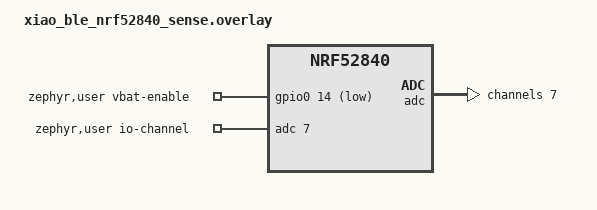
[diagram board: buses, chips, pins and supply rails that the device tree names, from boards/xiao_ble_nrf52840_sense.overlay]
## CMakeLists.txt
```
# AeroDrag Wheel — Zephyr application.
# Firmware SEPARATO (nRF52840) — NON fa parte del build ESP-IDF della repo madre.
cmake_minimum_required(VERSION 3.20.0)

find_package(Zephyr REQUIRED HINTS $ENV{ZEPHYR_BASE})
project(aerodrag_wheel)

target_sources(app PRIVATE
	src/main.c
	src/wheel_ble.c
	src/wheel_battery.c
	src/wheel_store.c
)
```

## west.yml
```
# AeroDrag Wheel — manifest west (app standalone su nRF Connect SDK).
#
# Uso (workspace-app, topologia T2):
#   west init -l .            # inizializza il workspace usando questo manifest
#   west update               # scarica NCS/Zephyr alla revisione sotto
#   west build -b xiao_ble/nrf52840/sense
#
# La revisione NCS è pinnata per riproducibilità: adeguala a quella che hai
# installato localmente se necessario (vedi README → bring-up).
manifest:
  remotes:
    - name: nrfconnect
      url-base: https://github.com/nrfconnect
  projects:
    - name: sdk-nrf
      remote: nrfconnect
      revision: v2.7.0
      import: true
  self:
    path: aerodrag-wheel
```

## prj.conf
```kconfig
# AeroDrag Wheel — Zephyr / nRF Connect SDK config
# Board: XIAO BLE Sense (xiao_ble/nrf52840/sense) — IMU LSM6DS3TR-C onboard + LiPo.

# ── BLE peripheral ───────────────────────────────────────────────────────────
CONFIG_BT=y
CONFIG_BT_PERIPHERAL=y
CONFIG_BT_DEVICE_NAME="AeroDrag Wheel"
CONFIG_BT_MAX_CONN=2
CONFIG_BT_GATT_CLIENT=n
CONFIG_BT_GATT_DYNAMIC_DB=y

# Bonding/cifratura del confine G (contract v0.3.4 §2.G): il link 0xBB00 DEVE essere
# cifrato + bondato (LE SM1, Level >=2). Just Works / NoInputNoOutput (default: nessun
# auth-cb con display/input) -> Level 2 *unauthenticated*, coerente col central ESP32
# (sm_sc=1, sm_mitm=0, NoInputNoOutput, key_dist ENC|ID, indirizzo pubblico statico).
# NON abilitare SC-only (CONFIG_BT_SMP_SC_PAIR_ONLY) o MITM qui: e' il passo 4
# anti-downgrade del rollout (seam #21); unilaterale staccherebbe il pairing.
CONFIG_BT_SMP=y
CONFIG_BT_BONDABLE=y
CONFIG_BT_SETTINGS=y
CONFIG_BT_FILTER_ACCEPT_LIST=y
CONFIG_BT_MAX_PAIRED=2

# Battery Service standard (0x180F) — addizione non-breaking, utile lato prodotto.
CONFIG_BT_BAS=y

# ── IMU onboard LSM6DS3TR-C (I2C interno) ───────────────────────────────────
# Il LSM6DS3TR-C è register-compatibile con la famiglia LSM6DSL. Se la tua
# versione di NCS dichiara l'IMU con un altro compatible, adegua qui (vedi README).
CONFIG_SENSOR=y
CONFIG_I2C=y
CONFIG_LSM6DSL=y
CONFIG_LSM6DSL_ENABLE_TEMP=y

# ── ADC + GPIO (lettura batteria LiPo del XIAO) ─────────────────────────────
CONFIG_ADC=y
CONFIG_GPIO=y

# ── Persistenza config + bond (Settings su NVS/flash) ───────────────────────
CONFIG_FLASH=y
CONFIG_FLASH_MAP=y
CONFIG_NVS=y
CONFIG_SETTINGS=y

# ── Floating point + stampa %f nei log ──────────────────────────────────────
CONFIG_FPU=y
CONFIG_CBPRINTF_FP_SUPPORT=y

# ── Stack ────────────────────────────────────────────────────────────────────
CONFIG_MAIN_STACK_SIZE=4096
CONFIG_SYSTEM_WORKQUEUE_STACK_SIZE=2048

# ── Logging ──────────────────────────────────────────────────────────────────
CONFIG_LOG=y
```

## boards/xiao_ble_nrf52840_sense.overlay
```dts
/*
 * Overlay XIAO BLE Sense — lettura batteria LiPo.
 *
 * Sul XIAO nRF52840 la tensione di batteria è su un partitore: il canale ADC è
 * AIN7 (P0.31) e l'enable del partitore è P0.14 (attivo basso). Verifica i pin
 * e il rapporto del partitore sulla TUA revisione board (vedi README/bring-up).
 *
 * L'IMU LSM6DS3TR-C è già dichiarata dalla board variant `/sense`: qui non serve
 * ridefinirla. Se la tua DTS non espone l'alias 'imu', il firmware usa comunque
 * il primo nodo st,lsm6dsl/lsm6dso okay (vedi src/main.c).
 */
#include <zephyr/dt-bindings/adc/adc.h>
#include <zephyr/dt-bindings/adc/nrf-saadc.h>
#include <zephyr/dt-bindings/gpio/gpio.h>

/ {
	zephyr,user {
		io-channels = <&adc 7>;
		vbat-enable-gpios = <&gpio0 14 GPIO_ACTIVE_LOW>;
	};
};

&adc {
	status = "okay";
	#address-cells = <1>;
	#size-cells = <0>;

	channel@7 {
		reg = <7>;
		zephyr,gain = "ADC_GAIN_1_6";
		zephyr,reference = "ADC_REF_INTERNAL";
		zephyr,acquisition-time = <ADC_ACQ_TIME(ADC_ACQ_TIME_MICROSECONDS, 10)>;
		zephyr,input-positive = <NRF_SAADC_AIN7>;
		zephyr,resolution = <12>;
	};
};
```

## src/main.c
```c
/*
 * AeroDrag Wheel — firmware sensore ruota Crr (coast-down).
 * Board: Seeed XIAO BLE Sense (nRF52840) — IMU onboard LSM6DS3TR-C (I2C) + LiPo.
 * Toolchain: nRF Connect SDK / Zephyr.   Build: west build -b xiao_ble/nrf52840/sense
 *
 * Espone il servizio BLE 0xBB00 (contract firmware↔wheel, §2.G). Consumer = ESP32
 * (BLE central) che relaya lo stream all'app (0xaa0c), inoltra i comandi coast-down
 * (0xaa0d→0xBB03) e scrive la config (0xaa08→0xBB04).
 *
 * ── MODELLO FISICO (montaggio sul MOZZO) ─────────────────────────────────────
 *   omega    = |gyro|  = √(gx²+gy²+gz²)      [rad/s]  (modulo: tilt-invariante)
 *   radius   = tireCircM / (2·pi)            [m]
 *   speedMs  = omega · radius                [m/s]    (v_center della finestra)
 *   accelMs2 = pendenza LS della finestra    [m/s²]   (decel coast-down = NEGATIVA)
 *   vibRMS   = RMS( |accel| - media_mobile ) [m/s²]   (rugosità superficie)
 *   tempC    = temperatura die IMU           [°C]
 *
 * speedMs/accelMs2 vengono da una REGRESSIONE LINEARE su finestra (v_center +
 * pendenza, riferiti allo stesso istante): elimina il bias da doppio low-pass
 * che sovrastimava il Crr. Vedi i commenti a ACCEL_WIN_N e a process_sample().
 *
 * CRITICO: il giroscopio va portato a FONDO-SCALA ±2000 dps (≈34.9 rad/s). Col
 * default ±245 dps saturerebbe a ~3 km/h e la misura sarebbe inutilizzabile.
 * A ±2000 dps il tetto è ~42 km/h su ruota 700c (omega·r): i coast-down partono
 * tipicamente ≤35 km/h; oltre il fondo-scala i campioni saturi vengono scartati.
 */
#include <zephyr/kernel.h>
#include <zephyr/device.h>
#include <zephyr/devicetree.h>
#include <zephyr/drivers/sensor.h>
#include <zephyr/logging/log.h>
#include <math.h>
#include <string.h>
#include <errno.h>

#include "wheel.h"

#if IS_ENABLED(CONFIG_BT_BAS)
#include <zephyr/bluetooth/services/bas.h>
#endif

LOG_MODULE_REGISTER(aerodrag_wheel, LOG_LEVEL_INF);

#define PI_F             3.14159265f

/* Cadenze: 100 Hz in coast-down (campionamento per accel/vib), 5 Hz in idle
 * (solo per restare reattivi; in idle non si trasmette → risparmio batteria). */
#define SAMPLE_HZ_ACTIVE 100
#define STREAM_DIV       10                       /* notify a 100/10 = 10 Hz   */
#define PERIOD_ACTIVE    K_MSEC(1000 / SAMPLE_HZ_ACTIVE)
#define PERIOD_IDLE      K_MSEC(200)
#define DT_S             (1.0f / SAMPLE_HZ_ACTIVE)

/* Vibrazione (rugosità superficie): media mobile del modulo |accel| */
#define VIB_MEAN_ALPHA   0.05f                    /* media mobile |accel|       */

/* Accelerazione longitudinale via REGRESSIONE LINEARE a finestra.
 * Sostituisce la vecchia cascata omega-LP → differenza finita → accel-LP, che
 * introduceva un lag differenziale fra speed e accel → bias del Crr (sovrastima
 * crescente con la velocità). La pendenza LS su una finestra uniforme è a
 * "fase-zero" al centro: v_center (media) e a_center (pendenza) sono riferiti
 * allo STESSO istante → coppia (v,a) coerente. 25 campioni @100 Hz = 250 ms:
 * media via il rumore gyro, la curvatura di a(v) sull'intervallo è trascurabile.
 * Tarare su HW se serve. */
#define ACCEL_WIN_N      25
#define ACCEL_WIN_MIN    8                        /* campioni minimi per stimare */
#define SPIN_LOG_RADS    5.0f                     /* soglia log asse dominante  */

/* IMU full-scale / ODR */
#define IMU_ODR_HZ       208
/* Fondo-scala gyro ±2000 dps, passato a sensor_attr_set come sensor_value
 * {val1, val2} = 34.906585 rad/s (sono i due campi di sensor_value, NON versioni). */
#define GYRO_FS_VAL1     34
#define GYRO_FS_VAL2     906585
#define GYRO_FS_RADS     34.906585f               /* ±2000 dps in rad/s         */
#define GYRO_SAT_RADS    (0.98f * GYRO_FS_RADS)   /* soglia clip/flat-top gyro  */
#define ACCEL_FS_MS2     157                      /* ≈ ±16 g                    */

/* Sicurezza: auto-annulla un coast-down che dura troppo (app sparita) */
#define MAX_RUN_MS       180000                   /* 3 min                      */

/* Batteria */
#define BATT_PERIOD      K_SECONDS(60)

/* ── IMU node (alias 'imu' o primo LSM6DSL/LSM6DSO okay della DTS) ──────────── */
#if DT_NODE_EXISTS(DT_ALIAS(imu))
#define IMU_NODE DT_ALIAS(imu)
#elif DT_HAS_COMPAT_STATUS_OKAY(st_lsm6dsl)
#define IMU_NODE DT_COMPAT_GET_ANY_STATUS_OKAY(st_lsm6dsl)
#elif DT_HAS_COMPAT_STATUS_OKAY(st_lsm6dso)
#define IMU_NODE DT_COMPAT_GET_ANY_STATUS_OKAY(st_lsm6dso)
#else
#error "IMU non trovata: definisci un alias 'imu' o abilita l'IMU onboard nella DTS"
#endif

/* ── Stato ─────────────────────────────────────────────────────────────────── */
static const struct device *g_imu;

static struct wheel_config g_cfg = {
	.tire_circ_m = WHEEL_TIRE_CIRC_DEFAULT,
	.mass_kg     = WHEEL_MASS_DEFAULT,
};
static volatile float g_radius_m = WHEEL_TIRE_CIRC_DEFAULT / (2.0f * PI_F);
static volatile enum coast_mode g_mode = COAST_IDLE;
static volatile bool g_cfg_dirty;     /* config da persistere a fine run (vedi set_config) */

static float clampf(float v, float lo, float hi)
{
	return v < lo ? lo : (v > hi ? hi : v);
}

/* ── API core invocate dal layer BLE ───────────────────────────────────────── */

int wheel_core_apply_cmd(uint8_t cmd)
{
	switch (cmd) {
	case COAST_CMD_INDOOR: g_mode = COAST_INDOOR; break;
	case COAST_CMD_OUT_A:  g_mode = COAST_OUT_A;  break;
	case COAST_CMD_OUT_B:  g_mode = COAST_OUT_B;  break;
	case COAST_CMD_CANCEL: g_mode = COAST_IDLE;   break;
	default:
		return -EINVAL;
	}
	LOG_INF("coast cmd=0x%02X → mode=%d", cmd, (int)g_mode);
	return 0;
}

void wheel_core_set_config(const struct wheel_config *cfg)
{
	g_cfg.tire_circ_m = clampf(cfg->tire_circ_m, WHEEL_TIRE_CIRC_MIN, WHEEL_TIRE_CIRC_MAX);
	g_cfg.mass_kg     = clampf(cfg->mass_kg, WHEEL_MASS_MIN, WHEEL_MASS_MAX);
	g_radius_m = g_cfg.tire_circ_m / (2.0f * PI_F);

	/* La PERSISTENZA su flash la fa SEMPRE il sample_thread (unico writer NVS →
	 * niente race su settings_save_one da due thread). Qui marchiamo solo "dirty".
	 * Durante un run il nuovo raggio vale dal run SUCCESSIVO: process_sample usa
	 * g_run_radius (snapshot a START), così una CONFIG ricevuta a metà corsa non
	 * altera il raggio in corsa (niente salto speed→accel → fit Crr protetto). */
	g_cfg_dirty = true;
	LOG_INF("config: circ=%.3f m mass=%.1f kg (r=%.4f m)%s",
		(double)g_cfg.tire_circ_m, (double)g_cfg.mass_kg, (double)g_radius_m,
		(g_mode == COAST_IDLE) ? "" : " [vale dal prossimo run]");
}

void wheel_core_get_config(struct wheel_config *out)
{
	*out = g_cfg;
}

/* ── Configurazione IMU (ODR + fondo-scala) ────────────────────────────────── */
static void imu_configure(const struct device *dev)
{
	struct sensor_value v;
	int rc;

	/* ODR accel + gyro */
	v.val1 = IMU_ODR_HZ; v.val2 = 0;
	rc = sensor_attr_set(dev, SENSOR_CHAN_ACCEL_XYZ, SENSOR_ATTR_SAMPLING_FREQUENCY, &v);
	if (rc) LOG_WRN("set accel ODR rc=%d (può essere impostato da DTS)", rc);
	v.val1 = IMU_ODR_HZ; v.val2 = 0;
	rc = sensor_attr_set(dev, SENSOR_CHAN_GYRO_XYZ, SENSOR_ATTR_SAMPLING_FREQUENCY, &v);
	if (rc) LOG_WRN("set gyro ODR rc=%d", rc);

	/* Fondo-scala accel ≈ ±16 g */
	v.val1 = ACCEL_FS_MS2; v.val2 = 0;
	rc = sensor_attr_set(dev, SENSOR_CHAN_ACCEL_XYZ, SENSOR_ATTR_FULL_SCALE, &v);
	if (rc) LOG_WRN("set accel FS rc=%d", rc);

	/* Fondo-scala gyro ±2000 dps — IL FIX CRITICO */
	v.val1 = GYRO_FS_VAL1; v.val2 = GYRO_FS_VAL2;
	rc = sensor_attr_set(dev, SENSOR_CHAN_GYRO_XYZ, SENSOR_ATTR_FULL_SCALE, &v);
	if (rc) {
		LOG_ERR("set gyro FS ±2000dps rc=%d — VERIFICARE: il default ±245dps "
			"satura a ~3 km/h!", rc);
	} else {
		LOG_INF("IMU: ODR=%d Hz, gyro ±2000 dps, accel ±16 g", IMU_ODR_HZ);
	}
}

/* ── Campionamento + calcolo + notify ──────────────────────────────────────── */

/* Stato run (resettato a ogni transizione IDLE→attivo).
 * Ring buffer della velocità grezza (omega·raggio) per la regressione: i campioni
 * sono equispaziati a DT_S, requisito della forma chiusa della pendenza LS. */
static float    g_speed_buf[ACCEL_WIN_N];   /* ring: speed grezza (omega·raggio) */
static bool     g_sat_buf[ACCEL_WIN_N];     /* ring: campione con gyro in clip    */
static uint8_t  g_buf_head;                 /* prossima posizione di scrittura    */
static uint8_t  g_buf_count;                /* campioni nel ring (≤ ACCEL_WIN_N)  */
static uint8_t  g_sat_in_win;               /* saturi attualmente in finestra     */
static float    g_run_radius;               /* raggio snapshot a START (no jump)  */
static float    g_am_mean;
static float    g_vib_acc;
static uint16_t g_vib_n;
static bool     g_vib_primed;
static float    g_temp_c = 20.0f;
static uint8_t  g_div;
static bool     g_spin_logged;
static uint32_t g_sat_log_n;                /* rate-limit log saturazione         */

static void run_reset(void)
{
	g_buf_head = 0; g_buf_count = 0; g_sat_in_win = 0;
	g_am_mean = 0; g_vib_acc = 0; g_vib_n = 0; g_vib_primed = false;
	g_div = 0; g_spin_logged = false; g_sat_log_n = 0;
	/* snapshot del raggio: una CONFIG (0xBB04) ricevuta a run attivo NON deve
	 * alterare il raggio usato in corsa (eviterebbe un salto di speed→accel). */
	g_run_radius = g_radius_m;
}

/* Media e pendenza LS di una finestra di campioni equispaziati (passo DT_S):
 *   v_center = media(speed)                                   [m/s]
 *   a_center = Σ(k-kc)·s_k / (DT_S·Σ(k-kc)²),  kc=(n-1)/2      [m/s²]
 * La retta LS passa per (t_center, media): i due valori sono allo STESSO istante
 * (centro finestra) → nessun lag differenziale fra v e a (no bias del Crr). */
static void regress_window(float *v_center, float *a_center)
{
	int n = g_buf_count;
	int start = (g_buf_head + ACCEL_WIN_N - n) % ACCEL_WIN_N;   /* più vecchio */
	float kc = (float)(n - 1) * 0.5f;
	float sum = 0.0f, num = 0.0f, den = 0.0f;

	for (int k = 0; k < n; k++) {
		float s = g_speed_buf[(start + k) % ACCEL_WIN_N];
		float dk = (float)k - kc;
		sum += s;
		num += dk * s;
		den += dk * dk;
	}
	*v_center = sum / (float)n;
	*a_center = (den > 0.0f) ? (num / (den * DT_S)) : 0.0f;
}

static void process_sample(void)
{
	struct sensor_value gyro[3], accel[3], temp;

	if (sensor_sample_fetch(g_imu) != 0) {
		return;
	}

	/* --- velocità angolare: MODULO del vettore gyro (tilt-invariante) ---
	 * Un solo asse |gyro[asse]| sottostima un mount obliquo di cos(tilt);
	 * il modulo √(gx²+gy²+gz²) recupera tutte le componenti di rotazione. */
	if (sensor_channel_get(g_imu, SENSOR_CHAN_GYRO_XYZ, gyro) == 0) {
		float gx = (float)sensor_value_to_double(&gyro[0]);
		float gy = (float)sensor_value_to_double(&gyro[1]);
		float gz = (float)sensor_value_to_double(&gyro[2]);

		/* saturazione: un asse a ~fondo-scala è flat-top → campione inaffidabile
		 * (un coast-down avviato troppo veloce darebbe decel ~0 = garbage). */
		bool sat = (fabsf(gx) >= GYRO_SAT_RADS) ||
			   (fabsf(gy) >= GYRO_SAT_RADS) ||
			   (fabsf(gz) >= GYRO_SAT_RADS);

		float omega = sqrtf(gx * gx + gy * gy + gz * gz);
		float speed = omega * g_run_radius;

		/* diagnostica: asse di spin dominante (solo log, non entra nel valore) */
		if (!g_spin_logged && omega > SPIN_LOG_RADS) {
			int mx = (fabsf(gx) >= fabsf(gy))
				 ? ((fabsf(gx) >= fabsf(gz)) ? 0 : 2)
				 : ((fabsf(gy) >= fabsf(gz)) ? 1 : 2);
			LOG_INF("spin rilevato: asse dominante %c (omega=%.1f rad/s)",
				"XYZ"[mx], (double)omega);
			g_spin_logged = true;
		}

		/* push nel ring (mantenuto uniforme nel tempo per la pendenza LS) */
		if (g_buf_count == ACCEL_WIN_N && g_sat_buf[g_buf_head]) {
			g_sat_in_win--;             /* esce un campione saturo */
		}
		g_speed_buf[g_buf_head] = speed;
		g_sat_buf[g_buf_head] = sat;
		if (sat) {
			g_sat_in_win++;
		}
		g_buf_head = (g_buf_head + 1) % ACCEL_WIN_N;
		if (g_buf_count < ACCEL_WIN_N) {
			g_buf_count++;
		}
	}

	/* --- vibrazione: RMS della componente AC del modulo accelerometrico --- */
	if (sensor_channel_get(g_imu, SENSOR_CHAN_ACCEL_XYZ, accel) == 0) {
		float ax = (float)sensor_value_to_double(&accel[0]);
		float ay = (float)sensor_value_to_double(&accel[1]);
		float az = (float)sensor_value_to_double(&accel[2]);
		float am = sqrtf(ax * ax + ay * ay + az * az);

		if (!g_vib_primed) {
			g_am_mean = am;             /* prime: no picco gonfio al warm-up */
			g_vib_primed = true;
		} else {
			g_am_mean += VIB_MEAN_ALPHA * (am - g_am_mean);
		}
		float dev = am - g_am_mean;
		g_vib_acc += dev * dev;
		g_vib_n++;
	}

	if (sensor_channel_get(g_imu, SENSOR_CHAN_DIE_TEMP, &temp) == 0) {
		g_temp_c = (float)sensor_value_to_double(&temp);
	}

	/* --- notify STREAM a 10 Hz --- */
	if (++g_div >= STREAM_DIV) {
		g_div = 0;
		float vib_rms = (g_vib_n > 0) ? sqrtf(g_vib_acc / (float)g_vib_n) : 0.0f;
		g_vib_acc = 0.0f;
		g_vib_n = 0;

		/* Finestra contaminata da saturazione → NON trasmettere: una coppia
		 * (v,a) corrotta entrerebbe nel fit Crr dell'app. Il wire 16B ratificato
		 * non ha un campo "stato"; sopprimere il frame è il modo conforme di far
		 * scartare il dato all'app. (Lo stato esplicito wheel→app è la seam #32,
		 * non ancora ratificata.) */
		if (g_sat_in_win > 0) {
			if ((g_sat_log_n++ % 10) == 0) {
				LOG_WRN("gyro saturo (>±2000 dps): frame soppresso "
					"(coast-down troppo veloce)");
			}
			return;
		}
		if (g_buf_count < ACCEL_WIN_MIN) {
			return;                     /* ancora pochi campioni per stimare */
		}

		float v_center, a_center;

		regress_window(&v_center, &a_center);

		if (wheel_ble_stream_subscribed()) {
			wheel_ble_stream_notify(v_center, a_center, g_temp_c, vib_rms);
		}
	}
}

static void sample_thread(void *p1, void *p2, void *p3)
{
	ARG_UNUSED(p1); ARG_UNUSED(p2); ARG_UNUSED(p3);

	enum coast_mode last = COAST_IDLE;
	int64_t run_start = 0;

	while (1) {
		enum coast_mode mode = g_mode;

		if (mode == COAST_IDLE) {
			last = COAST_IDLE;
			/* unico writer NVS: persiste la config "dirty" a riposo (entro
			 * ~200ms; durante un run resta dirty e si salva al ritorno IDLE). */
			if (g_cfg_dirty) {
				g_cfg_dirty = false;
				wheel_store_save(&g_cfg);
				LOG_INF("config persistita");
			}
			k_sleep(PERIOD_IDLE);
			continue;
		}

		if (mode != last) {           /* IDLE → attivo: nuovo run */
			run_reset();
			run_start = k_uptime_get();
			last = mode;
			LOG_INF("coast-down START (mode=%d)", (int)mode);
		}

		if (g_imu && device_is_ready(g_imu)) {
			process_sample();
		}

		if (k_uptime_get() - run_start > MAX_RUN_MS) {
			LOG_WRN("coast-down timeout → IDLE");
			g_mode = COAST_IDLE;
		}

		k_sleep(PERIOD_ACTIVE);
	}
}

K_THREAD_DEFINE(sample_tid, 2048, sample_thread, NULL, NULL, NULL, 7, 0, 0);

/* ── Batteria → Battery Service (best-effort) ──────────────────────────────── */
#if IS_ENABLED(CONFIG_BT_BAS)
static void batt_work_fn(struct k_work *work);
static K_WORK_DELAYABLE_DEFINE(batt_work, batt_work_fn);

static void batt_work_fn(struct k_work *work)
{
	uint8_t pct;

	if (wheel_battery_read_pct(&pct) == 0) {
		bt_bas_set_battery_level(pct);
	}
	k_work_reschedule(&batt_work, BATT_PERIOD);
}
#endif

/* ── main ──────────────────────────────────────────────────────────────────── */
int main(void)
{
	LOG_INF("AeroDrag Wheel — sensore ruota Crr (0xBB00)");

	wheel_store_init();
	wheel_store_load(&g_cfg);
	g_cfg.tire_circ_m = clampf(g_cfg.tire_circ_m, WHEEL_TIRE_CIRC_MIN, WHEEL_TIRE_CIRC_MAX);
	g_cfg.mass_kg     = clampf(g_cfg.mass_kg, WHEEL_MASS_MIN, WHEEL_MASS_MAX);
	g_radius_m = g_cfg.tire_circ_m / (2.0f * PI_F);

	g_imu = DEVICE_DT_GET(IMU_NODE);
	if (!device_is_ready(g_imu)) {
		LOG_ERR("IMU LSM6DS3TR-C non pronta — stream a zero finché non risponde");
	} else {
		imu_configure(g_imu);
		LOG_INF("IMU pronta");
	}

	wheel_battery_init();

	if (wheel_ble_init() != 0) {
		LOG_ERR("BLE init fallita");
		return 0;
	}

#if IS_ENABLED(CONFIG_BT_BAS)
	k_work_schedule(&batt_work, K_NO_WAIT);
#endif

	LOG_INF("pronto: in attesa di comando coast-down (0xBB03) dal central");
	return 0;
}
```

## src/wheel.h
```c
/*
 * AeroDrag Wheel — interfacce condivise fra i moduli del firmware.
 *
 * Firmware del sensore ruota Crr (coast-down). Espone il servizio BLE 0xBB00
 * (contract firmware↔wheel, §2.G). Consumer = ESP32 (BLE central), che relaya
 * lo stream all'app (0xaa0c), inoltra i comandi coast-down (da 0xaa0d → 0xBB03)
 * e scrive la config (circonferenza+massa) sul 0xBB04 (da CONFIG 0xaa08).
 *
 * Board: Seeed XIAO BLE Sense (nRF52840) — IMU onboard LSM6DS3TR-C + LiPo.
 */
#ifndef AERODRAG_WHEEL_H_
#define AERODRAG_WHEEL_H_

#include <stdbool.h>
#include <stdint.h>

/* ── Config (scritta dall'ESP32 via 0xBB04: float tireCircM + float massKg) ──
 * I range rispecchiano CONFIG 0xaa08 del firmware ESP32 (contract §2):
 *   massKg ∈ [33,200], wheelCircM/tireCircM ∈ [1.0,2.5].
 */
struct wheel_config {
	float tire_circ_m;   /* circonferenza ruota [m]  (== wheelCircM dell'app) */
	float mass_kg;       /* massa atleta+bici [kg]                            */
} __attribute__((packed));

#define WHEEL_TIRE_CIRC_DEFAULT 2.105f   /* 700x25c                          */
#define WHEEL_MASS_DEFAULT      78.0f
#define WHEEL_TIRE_CIRC_MIN     1.0f
#define WHEEL_TIRE_CIRC_MAX     2.5f
#define WHEEL_MASS_MIN          33.0f
#define WHEEL_MASS_MAX          200.0f

/* ── Comandi coast-down (0xBB03, 1 byte) — identici a WHEEL_CMD dell'app ──── */
enum coast_cmd {
	COAST_CMD_INDOOR  = 0x01,
	COAST_CMD_OUT_A   = 0x02,
	COAST_CMD_OUT_B   = 0x03,
	COAST_CMD_CANCEL  = 0xFF,
};

/* Stato coast-down interno */
enum coast_mode {
	COAST_IDLE = 0,
	COAST_INDOOR,
	COAST_OUT_A,
	COAST_OUT_B,
};

/* ── Core (main.c) — invocate dal layer BLE sulle scritture GATT ──────────── */

/* 0xBB03 write: applica un comando coast-down. Ritorna 0 se valido,
 * -EINVAL se il byte non è un comando noto (→ ATT error lato BLE). */
int  wheel_core_apply_cmd(uint8_t cmd);

/* 0xBB04 write: aggiorna la config (clampata ai range) e la persiste. */
void wheel_core_set_config(const struct wheel_config *cfg);

/* 0xBB04 read: copia la config corrente. */
void wheel_core_get_config(struct wheel_config *out);

/* ── BLE (wheel_ble.c) ────────────────────────────────────────────────────── */
int  wheel_ble_init(void);

/* True se un central è sottoscritto alle NOTIFY di STREAM (0xBB01). */
bool wheel_ble_stream_subscribed(void);

/* Invia una NOTIFY STREAM (0xBB01): 16 B LE = speedMs, accelMs2, tempC, vibRMS. */
void wheel_ble_stream_notify(float speed_ms, float accel_ms2,
			     float temp_c, float vib_rms);

/* ── Batteria (wheel_battery.c) ───────────────────────────────────────────── */
int  wheel_battery_init(void);
/* Legge la percentuale batteria [0..100]. Ritorna 0 ok, <0 se ADC non pronto. */
int  wheel_battery_read_pct(uint8_t *pct_out);

/* ── Persistenza config (wheel_store.c, Zephyr Settings/NVS) ──────────────── */
int  wheel_store_init(void);
/* Carica la config persistita in *cfg (se assente, lascia *cfg invariata). */
void wheel_store_load(struct wheel_config *cfg);
void wheel_store_save(const struct wheel_config *cfg);

#endif /* AERODRAG_WHEEL_H_ */
```

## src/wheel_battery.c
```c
/*
 * AeroDrag Wheel — monitoraggio batteria LiPo del XIAO BLE Sense.
 *
 * Sul XIAO nRF52840 la tensione di batteria si legge su un partitore:
 *   - pin di enable del partitore (P0.14, ATTIVO BASSO) → io abilitato dall'overlay
 *   - canale ADC su AIN7 (P0.31)                        → io-channels in zephyr,user
 *   - fattore partitore ≈ 2.96  (R 1M + 0.51M)
 *
 * Best-effort: se l'overlay non definisce l'ADC, le funzioni ritornano errore e
 * il resto del firmware funziona comunque (la batteria è una feature di prodotto,
 * non parte del contratto 0xBB00).
 *
 * NB bring-up: VERIFICARE pin/partitore sulla revisione esatta della board.
 */
#include <zephyr/kernel.h>
#include <zephyr/devicetree.h>
#include <zephyr/logging/log.h>
#include <errno.h>

#include "wheel.h"

LOG_MODULE_REGISTER(wheel_batt, LOG_LEVEL_INF);

/* Abilita il codice ADC solo se l'overlay fornisce il nodo zephyr,user con
 * io-channels (così il build non rompe su board senza la definizione). */
#if DT_NODE_EXISTS(DT_PATH(zephyr_user)) && DT_NODE_HAS_PROP(DT_PATH(zephyr_user), io_channels)

#include <zephyr/drivers/adc.h>
#include <zephyr/drivers/gpio.h>

#define VBAT_DIVIDER 2.96f          /* (1M + 0.51M) / 0.51M                    */
#define LIPO_FULL_MV 4200.0f
#define LIPO_EMPTY_MV 3300.0f

static const struct adc_dt_spec vbat_adc = ADC_DT_SPEC_GET(DT_PATH(zephyr_user));
static const struct gpio_dt_spec vbat_en =
	GPIO_DT_SPEC_GET_OR(DT_PATH(zephyr_user), vbat_enable_gpios, {0});

static bool s_ready;

int wheel_battery_init(void)
{
	if (!adc_is_ready_dt(&vbat_adc)) {
		LOG_WRN("ADC non pronto — batteria disabilitata");
		return -ENODEV;
	}
	if (adc_channel_setup_dt(&vbat_adc) < 0) {
		LOG_WRN("adc_channel_setup fallito — batteria disabilitata");
		return -EIO;
	}
	if (vbat_en.port && !gpio_is_ready_dt(&vbat_en)) {
		LOG_WRN("gpio enable batteria non pronto");
	}
	if (vbat_en.port) {
		gpio_pin_configure_dt(&vbat_en, GPIO_OUTPUT_INACTIVE);
	}
	s_ready = true;
	LOG_INF("batteria pronta (AIN VBAT)");
	return 0;
}

static uint8_t mv_to_pct(float mv)
{
	if (mv >= LIPO_FULL_MV) {
		return 100;
	}
	if (mv <= LIPO_EMPTY_MV) {
		return 0;
	}
	/* Curva LiPo approssimata (più fedele di una retta sui bordi). */
	float pct = (mv - LIPO_EMPTY_MV) / (LIPO_FULL_MV - LIPO_EMPTY_MV) * 100.0f;

	return (uint8_t)(pct + 0.5f);
}

int wheel_battery_read_pct(uint8_t *pct_out)
{
	int16_t raw = 0;
	struct adc_sequence seq = {
		.buffer = &raw,
		.buffer_size = sizeof(raw),
	};

	if (!s_ready || pct_out == NULL) {
		return -ENODEV;
	}

	if (vbat_en.port) {
		gpio_pin_set_dt(&vbat_en, 1);   /* attivo (basso fisico) → abilita partitore */
		k_sleep(K_MSEC(5));
	}

	(void)adc_sequence_init_dt(&vbat_adc, &seq);
	int rc = adc_read_dt(&vbat_adc, &seq);

	if (vbat_en.port) {
		gpio_pin_set_dt(&vbat_en, 0);   /* disabilita partitore (risparmio) */
	}

	if (rc < 0) {
		LOG_WRN("adc_read fallito (%d)", rc);
		return rc;
	}

	int32_t mv = raw;

	if (adc_raw_to_millivolts_dt(&vbat_adc, &mv) < 0) {
		return -EIO;
	}

	float vbat_mv = (float)mv * VBAT_DIVIDER;

	*pct_out = mv_to_pct(vbat_mv);
	LOG_DBG("vbat=%d mV → %u%%", (int)vbat_mv, *pct_out);
	return 0;
}

#else /* nessun ADC definito nell'overlay */

int wheel_battery_init(void)
{
	LOG_INF("batteria non configurata (nessun io-channels in zephyr,user)");
	return -ENOTSUP;
}

int wheel_battery_read_pct(uint8_t *pct_out)
{
	ARG_UNUSED(pct_out);
	return -ENOTSUP;
}

#endif
```

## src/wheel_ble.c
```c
/*
 * AeroDrag Wheel — layer BLE: servizio 0xBB00, advertising, gestione connessione.
 *
 *   0xBB01 STREAM  NOTIFY 10 Hz  16 B: float speedMs, accelMs2, tempC, vibRMS (LE)
 *   0xBB02 RESULT  NOTIFY         6 B: legacy, non usato (il Crr lo calcola l'app)
 *   0xBB03 CMD     WRITE          1 B: 0x01 indoor / 0x02 out-A / 0x03 out-B / 0xFF cancel
 *   0xBB04 CONFIG  READ+WRITE     8 B: float tireCircM + float massKg
 *
 * Espone anche il Battery Service standard (0x180F) — addizione non-breaking,
 * utile lato prodotto; il central può ignorarla.
 */
#include <zephyr/kernel.h>
#include <zephyr/bluetooth/bluetooth.h>
#include <zephyr/bluetooth/conn.h>
#include <zephyr/bluetooth/gatt.h>
#include <zephyr/bluetooth/uuid.h>
#include <zephyr/settings/settings.h>
#include <zephyr/logging/log.h>
#include <errno.h>
#include <string.h>

#include "wheel.h"

LOG_MODULE_REGISTER(wheel_ble, LOG_LEVEL_INF);

#define DEVNAME "AeroDrag Wheel"

/* UUID 16-bit del servizio/caratteristiche (base SIG) */
#define BT_UUID_WHEEL_SVC     BT_UUID_DECLARE_16(0xBB00)
#define BT_UUID_WHEEL_STREAM  BT_UUID_DECLARE_16(0xBB01)
#define BT_UUID_WHEEL_RESULT  BT_UUID_DECLARE_16(0xBB02)
#define BT_UUID_WHEEL_CMD     BT_UUID_DECLARE_16(0xBB03)
#define BT_UUID_WHEEL_CONFIG  BT_UUID_DECLARE_16(0xBB04)

static volatile bool s_stream_subscribed;
static int s_conn_count;          /* connessioni attive (gestione adv su bond_deleted) */

/* ── Handler GATT ──────────────────────────────────────────────────────────── */

static ssize_t cfg_read(struct bt_conn *conn, const struct bt_gatt_attr *attr,
			void *buf, uint16_t len, uint16_t offset)
{
	struct wheel_config cfg;

	wheel_core_get_config(&cfg);
	return bt_gatt_attr_read(conn, attr, buf, len, offset, &cfg, sizeof(cfg));
}

static ssize_t cfg_write(struct bt_conn *conn, const struct bt_gatt_attr *attr,
			 const void *buf, uint16_t len, uint16_t offset, uint8_t flags)
{
	struct wheel_config cfg;

	ARG_UNUSED(conn);
	ARG_UNUSED(attr);
	ARG_UNUSED(flags);

	if (offset != 0 || len != sizeof(cfg)) {
		return BT_GATT_ERR(BT_ATT_ERR_INVALID_ATTRIBUTE_LEN);
	}
	memcpy(&cfg, buf, sizeof(cfg));
	wheel_core_set_config(&cfg);   /* il core clampa + persiste */
	return len;
}

static ssize_t cmd_write(struct bt_conn *conn, const struct bt_gatt_attr *attr,
			 const void *buf, uint16_t len, uint16_t offset, uint8_t flags)
{
	ARG_UNUSED(conn);
	ARG_UNUSED(attr);
	ARG_UNUSED(flags);

	if (offset != 0 || len != 1) {
		return BT_GATT_ERR(BT_ATT_ERR_INVALID_ATTRIBUTE_LEN);
	}
	if (wheel_core_apply_cmd(((const uint8_t *)buf)[0]) != 0) {
		return BT_GATT_ERR(BT_ATT_ERR_VALUE_NOT_ALLOWED);
	}
	return len;
}

static void stream_ccc_cfg(const struct bt_gatt_attr *attr, uint16_t value)
{
	ARG_UNUSED(attr);
	s_stream_subscribed = (value == BT_GATT_CCC_NOTIFY);
	LOG_INF("STREAM notify %s", s_stream_subscribed ? "ON" : "OFF");
}

/* Tabella attributi del servizio 0xBB00. Indici:
 *   [0]=svc [1]=STREAM(decl) [2]=STREAM(val) [3]=STREAM CCC
 *   [4]=RESULT(decl) [5]=RESULT(val) [6]=RESULT CCC
 *   [7]=CMD(decl) [8]=CMD(val)
 *   [9]=CONFIG(decl) [10]=CONFIG(val)
 */
BT_GATT_SERVICE_DEFINE(wheel_svc,
	BT_GATT_PRIMARY_SERVICE(BT_UUID_WHEEL_SVC),

	/* (v0.3.4 §2.G) Sicurezza confine G: sottoscrizioni/scritture sensibili gated
	 * dietro cifratura (LE SM1 L≥2). GUARDRAIL: Just Works/NoInputNoOutput su
	 * entrambi i lati → Level 2 *unauthenticated* → si usa _ENCRYPT, NON _AUTHEN
	 * (con Just Works _AUTHEN non sarebbe mai soddisfatto → write rifiutate per
	 * sempre). Il wire/payload resta invariato. */
	BT_GATT_CHARACTERISTIC(BT_UUID_WHEEL_STREAM, BT_GATT_CHRC_NOTIFY,
			       BT_GATT_PERM_NONE, NULL, NULL, NULL),
	BT_GATT_CCC(stream_ccc_cfg, BT_GATT_PERM_READ | BT_GATT_PERM_WRITE_ENCRYPT),

	BT_GATT_CHARACTERISTIC(BT_UUID_WHEEL_RESULT, BT_GATT_CHRC_NOTIFY,
			       BT_GATT_PERM_NONE, NULL, NULL, NULL),
	BT_GATT_CCC(NULL, BT_GATT_PERM_READ | BT_GATT_PERM_WRITE_ENCRYPT),

	BT_GATT_CHARACTERISTIC(BT_UUID_WHEEL_CMD, BT_GATT_CHRC_WRITE,
			       BT_GATT_PERM_WRITE_ENCRYPT, NULL, cmd_write, NULL),

	BT_GATT_CHARACTERISTIC(BT_UUID_WHEEL_CONFIG,
			       BT_GATT_CHRC_READ | BT_GATT_CHRC_WRITE,
			       BT_GATT_PERM_READ | BT_GATT_PERM_WRITE_ENCRYPT,
			       cfg_read, cfg_write, NULL),
);

/* L'attributo "valore" di STREAM è alla posizione [2]. */
#define ATTR_STREAM_VAL (&wheel_svc.attrs[2])

bool wheel_ble_stream_subscribed(void)
{
	return s_stream_subscribed;
}

void wheel_ble_stream_notify(float speed_ms, float accel_ms2,
			     float temp_c, float vib_rms)
{
	/* 16 B little-endian (il nRF52840 è LE → il float[] è già nel layout giusto) */
	float frame[4] = { speed_ms, accel_ms2, temp_c, vib_rms };

	(void)bt_gatt_notify(NULL, ATTR_STREAM_VAL, frame, sizeof(frame));
}

/* ── Advertising + connessione + bonding (v0.3.4 §2.G) ─────────────────────── */

static const struct bt_data ad[] = {
	BT_DATA_BYTES(BT_DATA_FLAGS, BT_LE_AD_GENERAL | BT_LE_AD_NO_BREDR),
	BT_DATA_BYTES(BT_DATA_UUID16_ALL, 0x00, 0xBB),   /* 0xBB00, LE */
};
static const struct bt_data sd[] = {
	BT_DATA(BT_DATA_NAME_COMPLETE, DEVNAME, sizeof(DEVNAME) - 1),
};

/* Ripopola l'accept-list dai bond persistiti (callback di bt_foreach_bond). */
static void al_add_bond(const struct bt_bond_info *info, void *user_data)
{
	int *n = user_data;
	char s[BT_ADDR_LE_STR_LEN];

	if (bt_le_filter_accept_list_add(&info->addr) == 0) {
		bt_addr_le_to_str(&info->addr, s, sizeof(s));
		LOG_INF("accept-list += %s", s);
		(*n)++;
	}
}

/* Ricostruisce l'accept-list dai bond. Ritorna true se ne esiste ≥1. */
static bool rebuild_accept_list(void)
{
	int n = 0;

	bt_le_filter_accept_list_clear();
	bt_foreach_bond(BT_ID_DEFAULT, al_add_bond, &n);
	return n > 0;
}

static void advertising_start(void)
{
	/* GUARDRAIL #1 (il più pericoloso): filtrare con l'accept-list SOLO se esiste
	 * già un bond. Pubblicizzare con FILTER_CONN e lista VUOTA = nessuno può
	 * connettersi → device non accoppiabile PER SEMPRE. Senza bond → adv APERTO
	 * (bootstrap pairing); col bond ESP32 → adv filtrato verso quel solo peer. */
	/* preset connectable+scan. NB: BT_LE_ADV_CONN è deprecato da NCS 2.8 → al
	 * prossimo bump dell'SDK sostituire con BT_LE_ADV_CONN_FAST_2. */
	struct bt_le_adv_param param = *BT_LE_ADV_CONN;
	bool have_bond;
	int err;

	/* Stop preventivo: bt_le_adv_start NON ri-applica i parametri se l'adv è già
	 * attivo (ritorna -EALREADY) → per passare aperto↔filtrato bisogna ripartire. */
	(void)bt_le_adv_stop();

	have_bond = rebuild_accept_list();
	if (have_bond) {
		param.options |= BT_LE_ADV_OPT_FILTER_CONN |
				 BT_LE_ADV_OPT_FILTER_SCAN_REQ;
	}

	err = bt_le_adv_start(&param, ad, ARRAY_SIZE(ad), sd, ARRAY_SIZE(sd));
	if (err && err != -EALREADY) {
		LOG_ERR("adv start failed (%d)", err);
		return;
	}
	LOG_INF("advertising (svc 0xBB00, name '%s') — %s", DEVNAME,
		have_bond ? "accept-list (solo bond ESP32)" : "aperto (pairing)");
}

static void on_connected(struct bt_conn *conn, uint8_t err)
{
	int rc;

	if (err) {
		LOG_WRN("connection failed (0x%02x)", err);
		advertising_start();   /* riprova ad annunciarsi */
		return;
	}
	s_conn_count++;
	LOG_INF("central connesso → richiedo cifratura (L2)");
	/* GUARDRAIL #2: L2 (unauthenticated), NON L3+ — Just Works non soddisfa L3+
	 * → le write 0xBB03/04 verrebbero rifiutate per sempre. */
	rc = bt_conn_set_security(conn, BT_SECURITY_L2);
	if (rc) {
		LOG_WRN("bt_conn_set_security(L2) rc=%d", rc);
	}
}

static void on_disconnected(struct bt_conn *conn, uint8_t reason)
{
	ARG_UNUSED(conn);
	if (s_conn_count > 0) {
		s_conn_count--;
	}
	LOG_INF("central disconnesso (0x%02x) → riavvio advertising", reason);
	s_stream_subscribed = false;
	advertising_start();
}

static void on_security_changed(struct bt_conn *conn, bt_security_t level,
				enum bt_security_err err)
{
	ARG_UNUSED(conn);
	if (err) {
		LOG_WRN("cifratura FALLITA (level %d, err %d) — scritture 0xBB03/04 "
			"resteranno rifiutate finché il link non è cifrato", level, err);
	} else {
		LOG_INF("link cifrato attivo: security level %d", level);
	}
}

BT_CONN_CB_DEFINE(conn_callbacks) = {
	.connected = on_connected,
	.disconnected = on_disconnected,
	.security_changed = on_security_changed,
};

/* Il bond ora esiste → il prossimo advertising_start (post-disconnect) applicherà
 * l'accept-list verso il solo ESP32. */
static void on_pairing_complete(struct bt_conn *conn, bool bonded)
{
	ARG_UNUSED(conn);
	LOG_INF("pairing complete (bonded=%d): enforcement cifratura confine G attivo",
		bonded);
}

/* GUARDRAIL #3: su bond cancellato si DEVE tornare ad adv aperto, altrimenti si
 * resterebbe filtrati verso un bond inesistente → non accoppiabile. Se siamo
 * connessi ci pensa on_disconnected; se siamo da soli con adv filtrato attivo,
 * riconciliamo subito (advertising_start fa stop+rebuild → lista vuota → aperto). */
static void on_bond_deleted(uint8_t id, const bt_addr_le_t *peer)
{
	ARG_UNUSED(id); ARG_UNUSED(peer);
	LOG_INF("bond cancellato → riconcilio advertising (re-pairing)");
	if (s_conn_count == 0) {
		advertising_start();
	}
}

static struct bt_conn_auth_info_cb auth_info_cb = {
	.pairing_complete = on_pairing_complete,
	.bond_deleted = on_bond_deleted,
};

int wheel_ble_init(void)
{
	int err = bt_enable(NULL);

	if (err) {
		LOG_ERR("bt_enable failed (%d)", err);
		return err;
	}

	/* Carica i bond persistiti PRIMA dell'advertising: se il bond ESP32 c'è già,
	 * si parte subito con l'accept-list (niente finestra aperta superflua). */
	if (IS_ENABLED(CONFIG_SETTINGS)) {
		settings_load();
	}

	(void)bt_conn_auth_info_cb_register(&auth_info_cb);

	advertising_start();
	return 0;
}
```

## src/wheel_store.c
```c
/*
 * AeroDrag Wheel — persistenza della config (tireCircM + massKg) via Zephyr
 * Settings/NVS. L'ESP32 riscrive comunque la config a ogni connessione
 * (da CONFIG 0xaa08 → 0xBB04), ma persistere evita una finestra con i default
 * dopo un riavvio e dà un comportamento da prodotto.
 */
#include <zephyr/kernel.h>
#include <zephyr/logging/log.h>
#include <errno.h>
#include <string.h>

#include "wheel.h"

LOG_MODULE_REGISTER(wheel_store, LOG_LEVEL_INF);

#if IS_ENABLED(CONFIG_SETTINGS)

#include <zephyr/settings/settings.h>

#define KEY_ROOT "wheel"
#define KEY_CFG  "wheel/cfg"

static struct wheel_config s_cached;
static bool s_have;

static int wheel_settings_set(const char *name, size_t len,
			      settings_read_cb read_cb, void *cb_arg)
{
	const char *next;

	if (settings_name_steq(name, "cfg", &next) && !next) {
		if (len != sizeof(s_cached)) {
			return -EINVAL;
		}
		ssize_t rc = read_cb(cb_arg, &s_cached, sizeof(s_cached));

		if (rc >= 0) {
			s_have = true;
			return 0;
		}
		return (int)rc;
	}
	return -ENOENT;
}

SETTINGS_STATIC_HANDLER_DEFINE(wheel, KEY_ROOT, NULL, wheel_settings_set,
			      NULL, NULL);

int wheel_store_init(void)
{
	return settings_subsys_init();
}

void wheel_store_load(struct wheel_config *cfg)
{
	if (s_have && cfg != NULL) {
		*cfg = s_cached;
		LOG_INF("config caricata: circ=%.3f mass=%.1f",
			(double)cfg->tire_circ_m, (double)cfg->mass_kg);
	}
}

void wheel_store_save(const struct wheel_config *cfg)
{
	if (cfg == NULL) {
		return;
	}
	s_cached = *cfg;
	s_have = true;

	int rc = settings_save_one(KEY_CFG, cfg, sizeof(*cfg));

	if (rc) {
		LOG_WRN("settings_save_one fallito (%d)", rc);
	}
}

#else /* Settings non abilitato: no-op (config solo in RAM) */

int wheel_store_init(void)
{
	return 0;
}

void wheel_store_load(struct wheel_config *cfg)
{
	ARG_UNUSED(cfg);
}

void wheel_store_save(const struct wheel_config *cfg)
{
	ARG_UNUSED(cfg);
}

#endif /* CONFIG_SETTINGS */
```
